# uart register map
Vendor: Texas Instruments
Peripheral module from a debugger description file (folder Keystone2).
Registers are 32-bit, read-write, no defined reset value unless marked. A register's access mark holds for its fields unless they carry their own. Offsets are as the file gives them; lines under a group give offsets from that group; [hi:lo] are bit positions; {n}, {i} and the like mark numbered series; 'fields as' and 'values as' point back to an identical list; <NAME> marks a mode.

## UART_1
0x00 rbr
  [7:0] data
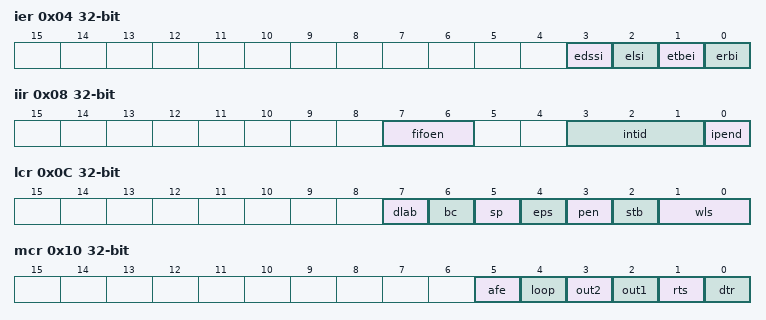
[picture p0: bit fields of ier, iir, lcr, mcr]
0x04 ier
  [3] edssi, [2] elsi, [1] etbei, [0] erbi
0x08 iir
  [7:6] fifoen, [3:1] intid, [0] ipend
0x0C lcr
  [7] dlab, [6] bc, [5] sp, [4] eps, [3] pen, [2] stb, [1:0] wls
0x10 mcr
  [5] afe, [4] loop, [3] out2, [2] out1, [1] rts, [0] dtr
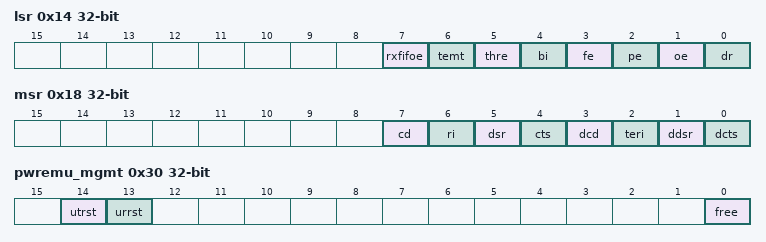
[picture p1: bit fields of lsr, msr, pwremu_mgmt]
0x14 lsr
  [7] rxfifoe, [6] temt, [5] thre, [4] bi, [3] fe, [2] pe, [1] oe, [0] dr
0x18 msr
  [7] cd, [6] ri, [5] dsr, [4] cts, [3] dcd, [2] teri, [1] ddsr, [0] dcts
0x1C scr
  [7:0] scr
0x20 dll
  [7:0] dll
0x24 dlh
  [7:0] dlh
0x28 revid1
  [31:0] rev
0x2C revid2
  [31:0] rev
0x30 pwremu_mgmt
  [14] utrst, [13] urrst, [0] free
0x34 mdr
  [0] osm_sel
